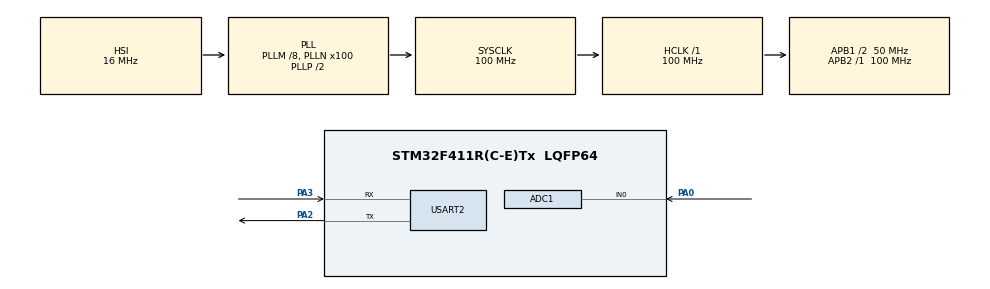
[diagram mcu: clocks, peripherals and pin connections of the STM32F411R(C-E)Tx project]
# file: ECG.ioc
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ADC1.Channel-0\#ChannelRegularConversion=ADC_CHANNEL_0
ADC1.ContinuousConvMode=DISABLE
ADC1.NbrOfConversion=1
ADC1.NbrOfConversionFlag=1
ADC1.Rank-0\#ChannelRegularConversion=1
ADC1.SamplingTime-0\#ChannelRegularConversion=ADC_SAMPLETIME_56CYCLES
ADC1.master=1
Mcu.Family=STM32F4
Mcu.Name=STM32F411R(C-E)Tx
Mcu.Package=LQFP64
NVIC.PriorityGroup=NVIC_PRIORITYGROUP_4
NVIC.RCC_IRQn=true\:0\:0\:false\:false\:true\:true\:false\:true
NVIC.TIM1_UP_TIM10_IRQn=true\:0\:0\:false\:false\:true\:true\:true\:true
NVIC.TIM2_IRQn=true\:0\:0\:false\:false\:true\:true\:true\:true
NVIC.USART2_IRQn=true\:0\:0\:false\:false\:true\:true\:true\:true
PA0-WKUP.Signal=ADCx_IN0
PA13.Mode=Serial_Wire
PA13.Signal=SYS_JTMS-SWDIO
PA14.Mode=Serial_Wire
PA14.Signal=SYS_JTCK-SWCLK
PA2.Mode=Asynchronous
PA2.Signal=USART2_TX
PA3.Mode=Asynchronous
PA3.Signal=USART2_RX
PH0\ -\ OSC_IN.Mode=HSE-External-Clock-Source
PH0\ -\ OSC_IN.Signal=RCC_OSC_IN
PH1\ -\ OSC_OUT.Mode=HSE-External-Clock-Source
PH1\ -\ OSC_OUT.Signal=RCC_OSC_OUT
ProjectManager.HeapSize=0x200
ProjectManager.StackSize=0x400
ProjectManager.TargetToolchain=STM32CubeIDE
RCC.48MHZClocksFreq_Value=50000000
RCC.AHBFreq_Value=100000000
RCC.APB1CLKDivider=RCC_HCLK_DIV2
RCC.APB1Freq_Value=50000000
RCC.APB1TimFreq_Value=100000000
RCC.APB2Freq_Value=100000000
RCC.APB2TimFreq_Value=100000000
RCC.CortexFreq_Value=100000000
RCC.HCLKFreq_Value=100000000
RCC.HSE_VALUE=25000000
RCC.HSI_VALUE=16000000
RCC.LSE_VALUE=32768
RCC.PLLM=8
RCC.PLLN=100
RCC.SYSCLKFreq_VALUE=100000000
RCC.SYSCLKSource=RCC_SYSCLKSOURCE_PLLCLK
RCC.VCOOutputFreq_Value=200000000
SH.ADCx_IN0.0=ADC1_IN0,IN0
TIM1.Period=99
TIM1.Prescaler=9999
TIM2.Period=99
TIM2.Prescaler=9999
USART2.VirtualMode=VM_ASYNC
VP_TIM1_VS_ClockSourceINT.Mode=Internal
VP_TIM2_VS_ClockSourceINT.Mode=Internal
board=custom

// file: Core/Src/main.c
/* USER CODE BEGIN Header */
/**
  ******************************************************************************
  * @file           : main.c
  * @brief          : STM32 ECG Raw ADC UART Streaming
  ******************************************************************************
  * Output format to Python:
  *   sample_index,ADCValue,Smooth_ECG\r\n
  *
  * Example:
  *   0,1870,1860
  *   1,1872,1861
  ******************************************************************************
  */
/* USER CODE END Header */
#include "main.h"
#include "adc.h"
#include "tim.h"
#include "usart.h"
#include "gpio.h"

/* USER CODE BEGIN Includes */
#include <stdio.h>
#include <string.h>
/* USER CODE END Includes */

/* USER CODE BEGIN PTD */
#define NUM_READINGS 5
/* USER CODE END PTD */

/* USER CODE BEGIN PV */
uint32_t ADCValue = 0;
uint32_t Smooth_ECG = 0;

uint8_t RcvData[96];
volatile uint8_t ADC_ON = 0;

/* Moving average smoothing */
uint32_t window[NUM_READINGS] = {0};
uint32_t readIndex = 0;
uint32_t total = 0;

/* Python timestamp용 sample index */
uint32_t sample_index = 0;
/* USER CODE END PV */

void SystemClock_Config(void);

/* USER CODE BEGIN 0 */
void HAL_TIM_PeriodElapsedCallback(TIM_HandleTypeDef *htim)
{
    if (htim->Instance == TIM1)
    {
        ADC_ON = 1;
    }
}
/* USER CODE END 0 */

int main(void)
{

  /* MCU Configuration--------------------------------------------------------*/

  /* Reset of all peripherals, Initializes the Flash interface and the Systick. */
  HAL_Init();

  /* Configure the system clock */
  SystemClock_Config();

  /* Initialize all configured peripherals */
  MX_GPIO_Init();
  MX_ADC1_Init();
  MX_TIM1_Init();
  MX_USART2_UART_Init();
  MX_TIM2_Init();
  /* USER CODE BEGIN 2 */
  /*
   * TIM1 interrupt start.
   *
   * CubeMX TIM1 target for 100 Hz when TIM1 clock = 100 MHz:
   *   Prescaler      = 9999
   *   Counter Period = 99
   *
   * Python expects:
   *   sample_index,ADCValue,Smooth_ECG
   */
  HAL_TIM_Base_Start_IT(&htim1);
  /* USER CODE END 2 */

  /* Infinite loop */
  while (1)
  {

    /* USER CODE BEGIN 3 */
    if (ADC_ON == 1)
    {
        ADC_ON = 0;

        /* 1. ADC read */
        HAL_ADC_Start(&hadc1);
        HAL_ADC_PollForConversion(&hadc1, 10);
        ADCValue = HAL_ADC_GetValue(&hadc1);
        HAL_ADC_Stop(&hadc1);

        /* 2. Moving average smoothing, window = 5 */
        total -= window[readIndex];
        window[readIndex] = ADCValue;
        total += window[readIndex];

        readIndex++;
        if (readIndex >= NUM_READINGS)
        {
            readIndex = 0;
        }

        Smooth_ECG = total / NUM_READINGS;

        /*
         * 3. UART transmit
         *
         * Python input format:
         * sample_index,ADCValue,Smooth_ECG
         */
        sprintf((char*)RcvData, "%lu,%lu,%lu\r\n",
                sample_index,
                ADCValue,
                Smooth_ECG);

        HAL_UART_Transmit(&huart2, RcvData, strlen((char*)RcvData), 10);

        sample_index++;
    }
  }
  /* USER CODE END 3 */
}

void SystemClock_Config(void)
{
  RCC_OscInitTypeDef RCC_OscInitStruct = {0};
  RCC_ClkInitTypeDef RCC_ClkInitStruct = {0};

  /** Configure the main internal regulator output voltage
  */
  __HAL_RCC_PWR_CLK_ENABLE();
  __HAL_PWR_VOLTAGESCALING_CONFIG(PWR_REGULATOR_VOLTAGE_SCALE1);

  /** Initializes the RCC Oscillators according to the specified parameters
  * in the RCC_OscInitTypeDef structure.
  */
  RCC_OscInitStruct.OscillatorType = RCC_OSCILLATORTYPE_HSI;
  RCC_OscInitStruct.HSIState = RCC_HSI_ON;
  RCC_OscInitStruct.HSICalibrationValue = RCC_HSICALIBRATION_DEFAULT;
  RCC_OscInitStruct.PLL.PLLState = RCC_PLL_ON;
  RCC_OscInitStruct.PLL.PLLSource = RCC_PLLSOURCE_HSI;
  RCC_OscInitStruct.PLL.PLLM = 8;
  RCC_OscInitStruct.PLL.PLLN = 100;
  RCC_OscInitStruct.PLL.PLLP = RCC_PLLP_DIV2;
  RCC_OscInitStruct.PLL.PLLQ = 4;
  if (HAL_RCC_OscConfig(&RCC_OscInitStruct) != HAL_OK)
  {
    Error_Handler();
  }

  /** Initializes the CPU, AHB and APB buses clocks
  */
  RCC_ClkInitStruct.ClockType = RCC_CLOCKTYPE_HCLK|RCC_CLOCKTYPE_SYSCLK
                              |RCC_CLOCKTYPE_PCLK1|RCC_CLOCKTYPE_PCLK2;
  RCC_ClkInitStruct.SYSCLKSource = RCC_SYSCLKSOURCE_PLLCLK;
  RCC_ClkInitStruct.AHBCLKDivider = RCC_SYSCLK_DIV1;
  RCC_ClkInitStruct.APB1CLKDivider = RCC_HCLK_DIV2;
  RCC_ClkInitStruct.APB2CLKDivider = RCC_HCLK_DIV1;

  if (HAL_RCC_ClockConfig(&RCC_ClkInitStruct, FLASH_LATENCY_3) != HAL_OK)
  {
    Error_Handler();
  }
}

void Error_Handler(void)
{
  __disable_irq();
  while (1)
  {
  }
}
